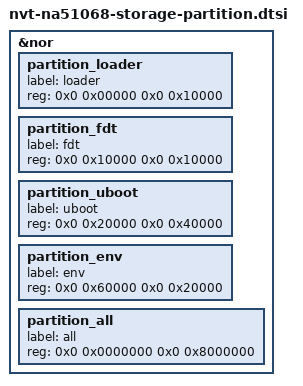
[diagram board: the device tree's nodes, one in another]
/*
 * Novatek Ltd. NA51068 BSP part of dts
 *
 * Cortex-A9
 *
 */

&nor {
	partition_loader {      label = "loader";       reg = <0x0 0x00000   0x0 0x10000>; }; /* Fixed */
	partition_fdt {	        label = "fdt";	        reg = <0x0 0x10000   0x0 0x10000>; }; /* Fixed */
	partition_uboot {       label = "uboot";        reg = <0x0 0x20000   0x0 0x40000>; };
	partition_env {         label = "env";          reg = <0x0 0x60000   0x0 0x20000>; };
	partition_all {  	label = "all";          reg = <0x0 0x0000000 0x0 0x8000000>; };
};
